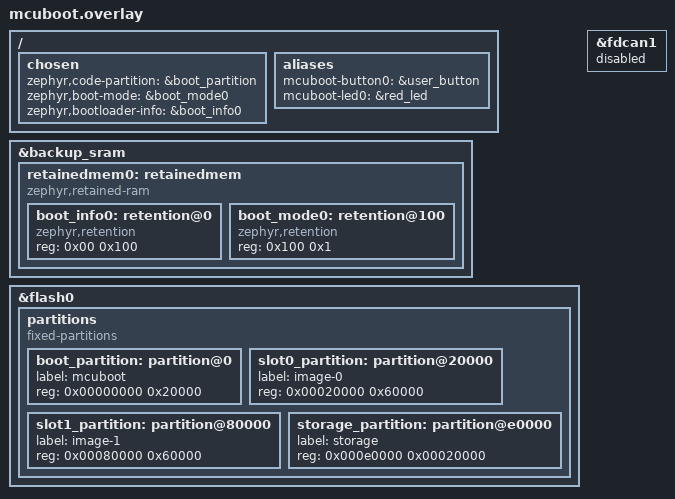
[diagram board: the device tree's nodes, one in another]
/ {
	chosen {
		zephyr,code-partition = &boot_partition;
		zephyr,boot-mode = &boot_mode0;
		zephyr,bootloader-info = &boot_info0;
	};
	aliases {
		mcuboot-button0 = &user_button;
		mcuboot-led0 = &red_led;
    };
};

&backup_sram {
	retainedmem0: retainedmem {
		compatible = "zephyr,retained-ram";
		status = "okay";
		#address-cells = <1>;
		#size-cells = <1>;

		boot_info0: retention@0 {
			compatible = "zephyr,retention";
			status = "okay";
			reg = <0x00 0x100>;
		};
		boot_mode0: retention@100 {
			compatible = "zephyr,retention";
			status = "okay";
			reg = <0x100 0x1>;
		};
	};
};

&flash0 {
	partitions {
		compatible = "fixed-partitions";
		#address-cells = <1>;
		#size-cells = <1>;

		boot_partition: partition@0 {
			label = "mcuboot";
			reg = <0x00000000 0x20000>;
		};
		slot0_partition: partition@20000 {
			label = "image-0";
			reg = <0x00020000 0x60000>;
		};
		slot1_partition: partition@80000 {
			label = "image-1";
			reg = <0x00080000 0x60000>;
		};

		storage_partition: partition@e0000 {
			label = "storage";
			reg = <0x000e0000 0x00020000>;
		};
	};
};

&fdcan1 {
	status = "disabled";
};
